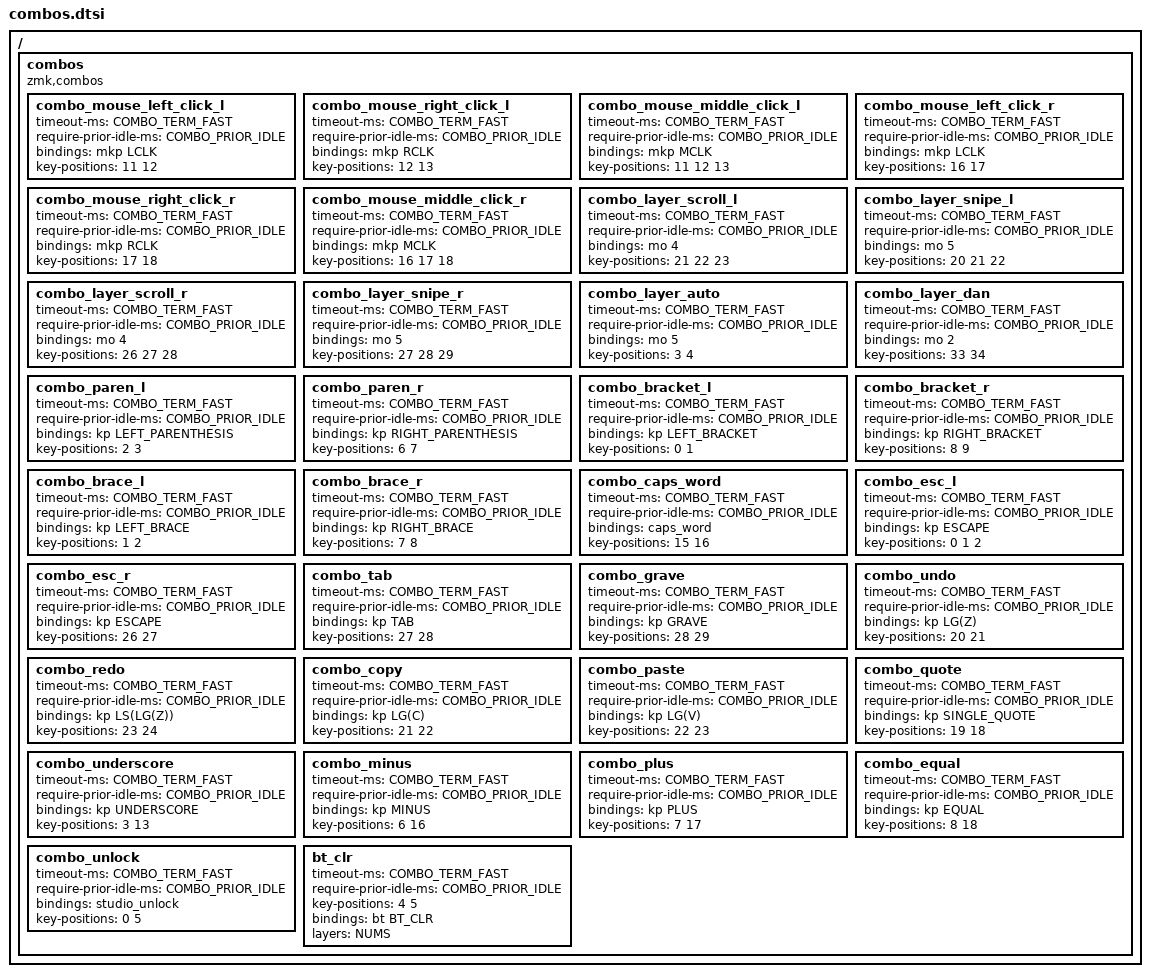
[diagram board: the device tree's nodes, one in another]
/ {
    combos {
        compatible = "zmk,combos";

        //INFO: Mouse clicks - left hand
        combo_mouse_left_click_l {
            timeout-ms = <COMBO_TERM_FAST>;
            require-prior-idle-ms = <COMBO_PRIOR_IDLE>;
            bindings = <&mkp LCLK>;
            key-positions = <11 12>;
        };

        combo_mouse_right_click_l {
            timeout-ms = <COMBO_TERM_FAST>;
            require-prior-idle-ms = <COMBO_PRIOR_IDLE>;
            bindings = <&mkp RCLK>;
            key-positions = <12 13>;
        };

        combo_mouse_middle_click_l {
            timeout-ms = <COMBO_TERM_FAST>;
            require-prior-idle-ms = <COMBO_PRIOR_IDLE>;
            bindings = <&mkp MCLK>;
            key-positions = <11 12 13>;
        };

        //INFO: Mouse clicks - right hand
        combo_mouse_left_click_r {
            timeout-ms = <COMBO_TERM_FAST>;
            require-prior-idle-ms = <COMBO_PRIOR_IDLE>;
            bindings = <&mkp LCLK>;
            key-positions = <16 17>;
        };

        combo_mouse_right_click_r {
            timeout-ms = <COMBO_TERM_FAST>;
            require-prior-idle-ms = <COMBO_PRIOR_IDLE>;
            bindings = <&mkp RCLK>;
            key-positions = <17 18>;
        };

        combo_mouse_middle_click_r {
            timeout-ms = <COMBO_TERM_FAST>;
            require-prior-idle-ms = <COMBO_PRIOR_IDLE>;
            bindings = <&mkp MCLK>;
            key-positions = <16 17 18>;
        };

        //INFO: Layer activation
        combo_layer_scroll_l {
            timeout-ms = <COMBO_TERM_FAST>;
            require-prior-idle-ms = <COMBO_PRIOR_IDLE>;
            bindings = <&mo 4>;
            key-positions = <21 22 23>;
        };

        combo_layer_snipe_l {
            timeout-ms = <COMBO_TERM_FAST>;
            require-prior-idle-ms = <COMBO_PRIOR_IDLE>;
            bindings = <&mo 5>;
            key-positions = <20 21 22>;
        };

        combo_layer_scroll_r {
            timeout-ms = <COMBO_TERM_FAST>;
            require-prior-idle-ms = <COMBO_PRIOR_IDLE>;
            bindings = <&mo 4>;
            key-positions = <26 27 28>;
        };

        combo_layer_snipe_r {
            timeout-ms = <COMBO_TERM_FAST>;
            require-prior-idle-ms = <COMBO_PRIOR_IDLE>;
            bindings = <&mo 5>;
            key-positions = <27 28 29>;
        };

        combo_layer_auto {
            timeout-ms = <COMBO_TERM_FAST>;
            require-prior-idle-ms = <COMBO_PRIOR_IDLE>;
            bindings = <&mo 5>;
            key-positions = <3 4>;
        };

        combo_layer_dan {
            timeout-ms = <COMBO_TERM_FAST>;
            require-prior-idle-ms = <COMBO_PRIOR_IDLE>;
            bindings = <&mo 2>;
            key-positions = <33 34>;
        };

        //INFO: Brackets and braces
        combo_paren_l {
            timeout-ms = <COMBO_TERM_FAST>;
            require-prior-idle-ms = <COMBO_PRIOR_IDLE>;
            bindings = <&kp LEFT_PARENTHESIS>;
            key-positions = <2 3>;
        };

        combo_paren_r {
            timeout-ms = <COMBO_TERM_FAST>;
            require-prior-idle-ms = <COMBO_PRIOR_IDLE>;
            bindings = <&kp RIGHT_PARENTHESIS>;
            key-positions = <6 7>;
        };

        combo_bracket_l {
            timeout-ms = <COMBO_TERM_FAST>;
            require-prior-idle-ms = <COMBO_PRIOR_IDLE>;
            bindings = <&kp LEFT_BRACKET>;
            key-positions = <0 1>;
        };

        combo_bracket_r {
            timeout-ms = <COMBO_TERM_FAST>;
            require-prior-idle-ms = <COMBO_PRIOR_IDLE>;
            bindings = <&kp RIGHT_BRACKET>;
            key-positions = <8 9>;
        };

        combo_brace_l {
            timeout-ms = <COMBO_TERM_FAST>;
            require-prior-idle-ms = <COMBO_PRIOR_IDLE>;
            bindings = <&kp LEFT_BRACE>;
            key-positions = <1 2>;
        };

        combo_brace_r {
            timeout-ms = <COMBO_TERM_FAST>;
            require-prior-idle-ms = <COMBO_PRIOR_IDLE>;
            bindings = <&kp RIGHT_BRACE>;
            key-positions = <7 8>;
        };

        //INFO: System commands
        combo_caps_word {
            timeout-ms = <COMBO_TERM_FAST>;
            require-prior-idle-ms = <COMBO_PRIOR_IDLE>;
            bindings = <&caps_word>;
            key-positions = <15 16>;
        };

        combo_esc_l {
            timeout-ms = <COMBO_TERM_FAST>;
            require-prior-idle-ms = <COMBO_PRIOR_IDLE>;
            bindings = <&kp ESCAPE>;
            key-positions = <0 1 2>;
        };

        combo_esc_r {
            timeout-ms = <COMBO_TERM_FAST>;
            require-prior-idle-ms = <COMBO_PRIOR_IDLE>;
            bindings = <&kp ESCAPE>;
            key-positions = <26 27>;
        };

        combo_tab {
            timeout-ms = <COMBO_TERM_FAST>;
            require-prior-idle-ms = <COMBO_PRIOR_IDLE>;
            bindings = <&kp TAB>;
            key-positions = <27 28>;
        };

        combo_grave {
            timeout-ms = <COMBO_TERM_FAST>;
            require-prior-idle-ms = <COMBO_PRIOR_IDLE>;
            bindings = <&kp GRAVE>;
            key-positions = <28 29>;
        };

        //INFO: Edit commands
        combo_undo {
            timeout-ms = <COMBO_TERM_FAST>;
            require-prior-idle-ms = <COMBO_PRIOR_IDLE>;
            bindings = <&kp LG(Z)>;
            key-positions = <20 21>;
        };

        combo_redo {
            timeout-ms = <COMBO_TERM_FAST>;
            require-prior-idle-ms = <COMBO_PRIOR_IDLE>;
            bindings = <&kp LS(LG(Z))>;
            key-positions = <23 24>;
        };

        combo_copy {
            timeout-ms = <COMBO_TERM_FAST>;
            require-prior-idle-ms = <COMBO_PRIOR_IDLE>;
            bindings = <&kp LG(C)>;
            key-positions = <21 22>;
        };

        combo_paste {
            timeout-ms = <COMBO_TERM_FAST>;
            require-prior-idle-ms = <COMBO_PRIOR_IDLE>;
            bindings = <&kp LG(V)>;
            key-positions = <22 23>;
        };

        //INFO: Special characters
        combo_quote {
            timeout-ms = <COMBO_TERM_FAST>;
            require-prior-idle-ms = <COMBO_PRIOR_IDLE>;
            bindings = <&kp SINGLE_QUOTE>;
            key-positions = <19 18>;
        };

        combo_underscore {
            timeout-ms = <COMBO_TERM_FAST>;
            require-prior-idle-ms = <COMBO_PRIOR_IDLE>;
            bindings = <&kp UNDERSCORE>;
            key-positions = <3 13>;
        };

        combo_minus {
            timeout-ms = <COMBO_TERM_FAST>;
            require-prior-idle-ms = <COMBO_PRIOR_IDLE>;
            bindings = <&kp MINUS>;
            key-positions = <6 16>;
        };

        combo_plus {
            timeout-ms = <COMBO_TERM_FAST>;
            require-prior-idle-ms = <COMBO_PRIOR_IDLE>;
            bindings = <&kp PLUS>;
            key-positions = <7 17>;
        };

        combo_equal {
            timeout-ms = <COMBO_TERM_FAST>;
            require-prior-idle-ms = <COMBO_PRIOR_IDLE>;
            bindings = <&kp EQUAL>;
            key-positions = <8 18>;
        };

        combo_unlock {
            timeout-ms = <COMBO_TERM_FAST>;
            require-prior-idle-ms = <COMBO_PRIOR_IDLE>;
            bindings = <&studio_unlock>;
            key-positions = <0 5>;
        };

        bt_clr {
            timeout-ms = <COMBO_TERM_FAST>;
            require-prior-idle-ms = <COMBO_PRIOR_IDLE>;
            key-positions = <4 5>;
            bindings = <&bt BT_CLR>;
            layers = <NUMS>;
        };
    };
};
